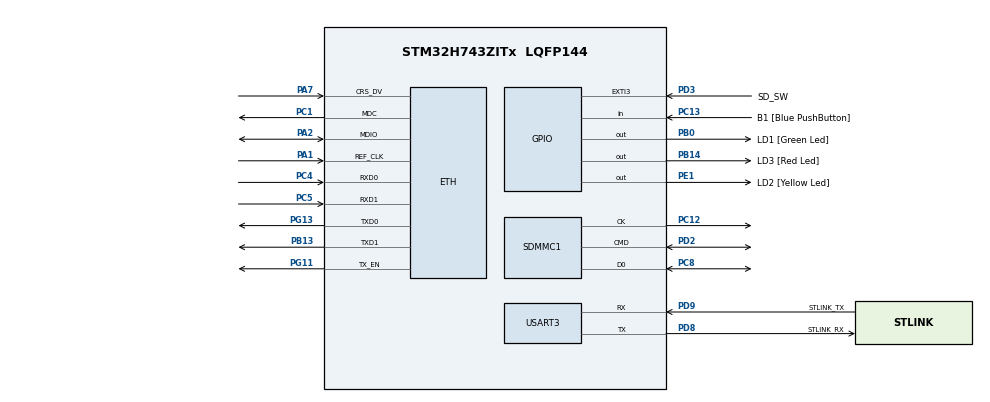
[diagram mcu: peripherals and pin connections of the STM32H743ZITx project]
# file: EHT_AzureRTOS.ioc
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CORTEX_M7.AccessPermission_S-Cortex_Memory_Protection_Unit_Region1_Settings_S=MPU_REGION_FULL_ACCESS
CORTEX_M7.AccessPermission_S-Cortex_Memory_Protection_Unit_Region2_Settings_S=MPU_REGION_FULL_ACCESS
CORTEX_M7.AccessPermission_Spec=MPU_REGION_NO_ACCESS
CORTEX_M7.BaseAddress_S-Cortex_Memory_Protection_Unit_Region1_Settings_S=0x24030000
CORTEX_M7.BaseAddress_S-Cortex_Memory_Protection_Unit_Region2_Settings_S=0x24030000
CORTEX_M7.CPU_DCache=Enabled
CORTEX_M7.CPU_ICache=Enabled
CORTEX_M7.Enable_S-Cortex_Memory_Protection_Unit_Region1_Settings_S=MPU_REGION_ENABLE
CORTEX_M7.Enable_S-Cortex_Memory_Protection_Unit_Region2_Settings_S=MPU_REGION_ENABLE
CORTEX_M7.IsBufferable_S-Cortex_Memory_Protection_Unit_Region2_Settings_S=MPU_ACCESS_BUFFERABLE
CORTEX_M7.Size_S-Cortex_Memory_Protection_Unit_Region1_Settings_S=MPU_REGION_SIZE_128KB
CORTEX_M7.Size_S-Cortex_Memory_Protection_Unit_Region2_Settings_S=MPU_REGION_SIZE_256B
CORTEX_M7.default_mode_Activation=1
ETH.MACAddr=00\:11\:83\:45\:26\:20
ETH.MediaInterface=HAL_ETH_RMII_MODE
ETH.RxDescAddress=0x24030000
ETH.TxDescAddress=0x24030060
Mcu.Family=STM32H7
Mcu.Name=STM32H743ZITx
Mcu.Package=LQFP144
NVIC.ETH_IRQn=true\:0\:0\:false\:false\:true\:false\:true\:true\:true
NVIC.EXTI3_IRQn=true\:0\:0\:false\:false\:true\:false\:true\:true\:true
NVIC.PriorityGroup=NVIC_PRIORITYGROUP_4
NVIC.SDMMC1_IRQn=true\:0\:0\:false\:false\:true\:false\:true\:true\:true
NVIC.TIM7_IRQn=true\:15\:0\:false\:false\:true\:false\:false\:true\:true
NVIC.TimeBase=TIM7_IRQn
NVIC.TimeBaseIP=TIM7
PA1.Mode=RMII
PA1.Signal=ETH_REF_CLK
PA11.Signal=USB_OTG_FS_DM
PA12.Signal=USB_OTG_FS_DP
PA13\ (JTMS/SWDIO).Mode=Trace_Asynchronous_SW
PA13\ (JTMS/SWDIO).Signal=DEBUG_JTMS-SWDIO
PA14\ (JTCK/SWCLK).Mode=Trace_Asynchronous_SW
PA14\ (JTCK/SWCLK).Signal=DEBUG_JTCK-SWCLK
PA2.Mode=RMII
PA2.Signal=ETH_MDIO
PA7.Mode=RMII
PA7.Signal=ETH_CRS_DV
PA8.Signal=USB_OTG_FS_SOF
PA9.Signal=USB_OTG_FS_VBUS
PB0.GPIO_Label=LD1 [Green Led]
PB0.Signal=GPIO_Output
PB13.Mode=RMII
PB13.Signal=ETH_TXD1
PB14.GPIO_Label=LD3 [Red Led]
PB14.Signal=GPIO_Output
PB3\ (JTDO/TRACESWO).Mode=Trace_Asynchronous_SW
PB3\ (JTDO/TRACESWO).Signal=DEBUG_JTDO-SWO
PC1.Mode=RMII
PC1.Signal=ETH_MDC
PC12.Mode=SD_1_bit
PC12.Signal=SDMMC1_CK
PC13.GPIO_Label=B1 [Blue PushButton]
PC13.Signal=GPIO_Input
PC14-OSC32_IN\ (OSC32_IN).Mode=LSE-External-Oscillator
PC14-OSC32_IN\ (OSC32_IN).Signal=RCC_OSC32_IN
PC15-OSC32_OUT\ (OSC32_OUT).Mode=LSE-External-Oscillator
PC15-OSC32_OUT\ (OSC32_OUT).Signal=RCC_OSC32_OUT
PC4.Mode=RMII
PC4.Signal=ETH_RXD0
PC5.Mode=RMII
PC5.Signal=ETH_RXD1
PC8.Mode=SD_1_bit
PC8.Signal=SDMMC1_D0
PD2.Mode=SD_1_bit
PD2.Signal=SDMMC1_CMD
PD3.GPIO_Label=SD_SW
PD3.Signal=GPXTI3
PD8.GPIO_Label=STLINK_RX
PD8.Mode=Asynchronous
PD8.Signal=USART3_TX
PD9.GPIO_Label=STLINK_TX
PD9.Mode=Asynchronous
PD9.Signal=USART3_RX
PE1.GPIO_Label=LD2 [Yellow Led]
PE1.Signal=GPIO_Output
PG11.Mode=RMII
PG11.Signal=ETH_TX_EN
PG13.Mode=RMII
PG13.Signal=ETH_TXD0
PH0-OSC_IN\ (PH0).Mode=HSE-External-Clock-Source
PH0-OSC_IN\ (PH0).Signal=RCC_OSC_IN
PH1-OSC_OUT\ (PH1).Signal=RCC_OSC_OUT
ProjectManager.HeapSize=0x200
ProjectManager.StackSize=0x400
ProjectManager.TargetToolchain=STM32CubeIDE
RCC.ADCFreq_Value=16125000
RCC.APB1Freq_Value=120000000
RCC.APB2Freq_Value=120000000
RCC.APB3Freq_Value=120000000
RCC.APB4Freq_Value=120000000
RCC.CortexFreq_Value=480000000
RCC.D1PPRE=RCC_APB3_DIV2
RCC.D2PPRE1=RCC_APB1_DIV2
RCC.D2PPRE2=RCC_APB2_DIV2
RCC.D3PPRE=RCC_APB4_DIV2
RCC.DIVM1=1
RCC.DIVN1=120
RCC.DIVQ1=10
RCC.HCLKFreq_Value=240000000
RCC.HPRE=RCC_HCLK_DIV2
RCC.HSE_VALUE=8000000
RCC.PLLFRACN=0
RCC.PLLSourceVirtual=RCC_PLLSOURCE_HSE
RCC.PWR_Regulator_Voltage_Scale=PWR_REGULATOR_VOLTAGE_SCALE2
RCC.SYSCLKFreq_VALUE=480000000
RCC.SYSCLKSource=RCC_SYSCLKSOURCE_PLLCLK
RCC.USBFreq_Value=96000000
STMicroelectronics.X-CUBE-AZRTOS-H7.3.1.0.FX_APP_MEM_POOL_SIZE=1024*4
STMicroelectronics.X-CUBE-AZRTOS-H7.3.1.0.FileXCcFileOoSystemJjFileXJjCore=true
STMicroelectronics.X-CUBE-AZRTOS-H7.3.1.0.Initialize_DHCP_protocol=true
STMicroelectronics.X-CUBE-AZRTOS-H7.3.1.0.Initialize_TCP_protocol=true
STMicroelectronics.X-CUBE-AZRTOS-H7.3.1.0.Initialize_UDP_protocol=true
STMicroelectronics.X-CUBE-AZRTOS-H7.3.1.0.InterfacesCcFileOoSystemJjFileXOoSDOointerface=true
STMicroelectronics.X-CUBE-AZRTOS-H7.3.1.0.InterfacesCcNetworkJjEthernetOoInterface=true
STMicroelectronics.X-CUBE-AZRTOS-H7.3.1.0.InterfacesCcNetworkJjEthernetOoPhyOoInterface=LAN8742IiPhyIiInterface
STMicroelectronics.X-CUBE-AZRTOS-H7.3.1.0.NX_APP_MEM_POOL_SIZE=45 * 1024
STMicroelectronics.X-CUBE-AZRTOS-H7.3.1.0.NX_ENABLE_INTERFACE_CAPABILITY=true
STMicroelectronics.X-CUBE-AZRTOS-H7.3.1.0.NetXDuoCcNetworkJjNetXDuoJjAddonsOoWebOoServer=true
STMicroelectronics.X-CUBE-AZRTOS-H7.3.1.0.NetXDuoCcNetworkJjNetXDuoJjNXOoCore=true
STMicroelectronics.X-CUBE-AZRTOS-H7.3.1.0.STM32CubeIiBSPIiComponentsCcBoardOoPartJjETHPhyJjLAN8742=true
STMicroelectronics.X-CUBE-AZRTOS-H7.3.1.0.TX_APP_MEM_POOL_SIZE=1024*2
STMicroelectronics.X-CUBE-AZRTOS-H7.3.1.0.ThreadXCcRTOSJjThreadXJjCore=true
STMicroelectronics.X-CUBE-AZRTOS-H7.3.1.0_IsAnAzureRtosMw=true
USART3.VirtualMode-Asynchronous=VM_ASYNC
VP_STMicroelectronics.X-CUBE-AZRTOS-H7_VS_BoardOoPartJjSTM32CubeIiBSPIiComponents_1.1.0_3.1.0.Mode=BoardOoPartJjSTM32CubeIiBSPIiComponents
VP_STMicroelectronics.X-CUBE-AZRTOS-H7_VS_FileOoSystemJjFileX_6.2.0_3.1.0.Mode=FileOoSystemJjFileX
VP_STMicroelectronics.X-CUBE-AZRTOS-H7_VS_FileOoSystemJjInterfaces_2.1.0_3.1.0.Mode=FileOoSystemJjInterfaces
VP_STMicroelectronics.X-CUBE-AZRTOS-H7_VS_NetworkJjInterfaces_2.1.0_3.1.0.Mode=NetworkJjInterfaces
VP_STMicroelectronics.X-CUBE-AZRTOS-H7_VS_NetworkJjNetXDuo_6.2.0_3.1.0.Mode=NetworkJjNetXDuo
VP_STMicroelectronics.X-CUBE-AZRTOS-H7_VS_RTOSJjThreadX_6.2.0_3.1.0.Mode=RTOSJjThreadX
VP_SYS_VS_tim7.Mode=TIM7
board=NUCLEO-H743ZI2

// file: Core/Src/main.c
/* USER CODE BEGIN Header */
/**
  ******************************************************************************
  * @file           : main.c
  * @brief          : Main program body
  ******************************************************************************
  * @attention
  *
  * Copyright (c) 2023 STMicroelectronics.
  * All rights reserved.
  *
  * This software is licensed under terms that can be found in the LICENSE file
  * in the root directory of this software component.
  * If no LICENSE file comes with this software, it is provided AS-IS.
  *
  ******************************************************************************
  */
/* USER CODE END Header */
#include "app_threadx.h"
#include "main.h"
#include "eth.h"
#include "sdmmc.h"
#include "usart.h"
#include "gpio.h"

void SystemClock_Config(void);
static void MPU_Initialize(void);
static void MPU_Config(void);

/* USER CODE BEGIN 0 */
int __io_putchar(int ch){
	ITM_SendChar(ch);
	HAL_UART_Transmit(&huart3, (uint8_t *)&ch, 1, 0xFFFF);
	return ch;
}
/* USER CODE END 0 */

int main(void)
{

  /* Enable I-Cache---------------------------------------------------------*/
  SCB_EnableICache();

  /* Enable D-Cache---------------------------------------------------------*/
  SCB_EnableDCache();

  /* MCU Configuration--------------------------------------------------------*/

  /* Reset of all peripherals, Initializes the Flash interface and the Systick. */
  HAL_Init();

  /* MPU Configuration--------------------------------------------------------*/
  MPU_Config();

  /* Configure the system clock */
  SystemClock_Config();

  /* Initialize all configured peripherals */
  MX_GPIO_Init();
  MX_ETH_Init();
  MX_USART3_UART_Init();
  MX_SDMMC1_SD_Init();

  MX_ThreadX_Init();

  /* We should never get here as control is now taken by the scheduler */
  /* Infinite loop */
  while (1)
  {

  }
}

void SystemClock_Config(void)
{
  RCC_OscInitTypeDef RCC_OscInitStruct = {0};
  RCC_ClkInitTypeDef RCC_ClkInitStruct = {0};

  /** Supply configuration update enable
  */
  HAL_PWREx_ConfigSupply(PWR_LDO_SUPPLY);

  /** Configure the main internal regulator output voltage
  */
  __HAL_PWR_VOLTAGESCALING_CONFIG(PWR_REGULATOR_VOLTAGE_SCALE1);
  while(!__HAL_PWR_GET_FLAG(PWR_FLAG_VOSRDY)) {}

  /** Initializes the RCC Oscillators according to the specified parameters
  * in the RCC_OscInitTypeDef structure.
  */
  RCC_OscInitStruct.OscillatorType = RCC_OSCILLATORTYPE_HSE;
  RCC_OscInitStruct.HSEState = RCC_HSE_BYPASS;
  RCC_OscInitStruct.PLL.PLLState = RCC_PLL_ON;
  RCC_OscInitStruct.PLL.PLLSource = RCC_PLLSOURCE_HSE;
  RCC_OscInitStruct.PLL.PLLM = 1;
  RCC_OscInitStruct.PLL.PLLN = 120;
  RCC_OscInitStruct.PLL.PLLP = 2;
  RCC_OscInitStruct.PLL.PLLQ = 10;
  RCC_OscInitStruct.PLL.PLLR = 2;
  RCC_OscInitStruct.PLL.PLLRGE = RCC_PLL1VCIRANGE_3;
  RCC_OscInitStruct.PLL.PLLVCOSEL = RCC_PLL1VCOWIDE;
  RCC_OscInitStruct.PLL.PLLFRACN = 0;
  if (HAL_RCC_OscConfig(&RCC_OscInitStruct) != HAL_OK)
  {
    Error_Handler();
  }

  /** Initializes the CPU, AHB and APB buses clocks
  */
  RCC_ClkInitStruct.ClockType = RCC_CLOCKTYPE_HCLK|RCC_CLOCKTYPE_SYSCLK
                              |RCC_CLOCKTYPE_PCLK1|RCC_CLOCKTYPE_PCLK2
                              |RCC_CLOCKTYPE_D3PCLK1|RCC_CLOCKTYPE_D1PCLK1;
  RCC_ClkInitStruct.SYSCLKSource = RCC_SYSCLKSOURCE_PLLCLK;
  RCC_ClkInitStruct.SYSCLKDivider = RCC_SYSCLK_DIV1;
  RCC_ClkInitStruct.AHBCLKDivider = RCC_HCLK_DIV2;
  RCC_ClkInitStruct.APB3CLKDivider = RCC_APB3_DIV2;
  RCC_ClkInitStruct.APB1CLKDivider = RCC_APB1_DIV2;
  RCC_ClkInitStruct.APB2CLKDivider = RCC_APB2_DIV2;
  RCC_ClkInitStruct.APB4CLKDivider = RCC_APB4_DIV2;

  if (HAL_RCC_ClockConfig(&RCC_ClkInitStruct, FLASH_LATENCY_4) != HAL_OK)
  {
    Error_Handler();
  }
}

/* MPU Configuration */

void MPU_Config(void)
{
  MPU_Region_InitTypeDef MPU_InitStruct = {0};

  /* Disables the MPU */
  HAL_MPU_Disable();

  /** Initializes and configures the Region and the memory to be protected
  */
  MPU_InitStruct.Enable = MPU_REGION_ENABLE;
  MPU_InitStruct.Number = MPU_REGION_NUMBER0;
  MPU_InitStruct.BaseAddress = 0x0;
  MPU_InitStruct.Size = MPU_REGION_SIZE_4GB;
  MPU_InitStruct.SubRegionDisable = 0x87;
  MPU_InitStruct.TypeExtField = MPU_TEX_LEVEL0;
  MPU_InitStruct.AccessPermission = MPU_REGION_NO_ACCESS;
  MPU_InitStruct.DisableExec = MPU_INSTRUCTION_ACCESS_DISABLE;
  MPU_InitStruct.IsShareable = MPU_ACCESS_SHAREABLE;
  MPU_InitStruct.IsCacheable = MPU_ACCESS_NOT_CACHEABLE;
  MPU_InitStruct.IsBufferable = MPU_ACCESS_NOT_BUFFERABLE;

  HAL_MPU_ConfigRegion(&MPU_InitStruct);

  /** Initializes and configures the Region and the memory to be protected
  */
  MPU_InitStruct.Number = MPU_REGION_NUMBER1;
  MPU_InitStruct.BaseAddress = 0x24030000;
  MPU_InitStruct.Size = MPU_REGION_SIZE_128KB;
  MPU_InitStruct.SubRegionDisable = 0x0;
  MPU_InitStruct.AccessPermission = MPU_REGION_FULL_ACCESS;
  MPU_InitStruct.DisableExec = MPU_INSTRUCTION_ACCESS_ENABLE;
  MPU_InitStruct.IsShareable = MPU_ACCESS_NOT_SHAREABLE;

  HAL_MPU_ConfigRegion(&MPU_InitStruct);

  /** Initializes and configures the Region and the memory to be protected
  */
  MPU_InitStruct.Number = MPU_REGION_NUMBER2;
  MPU_InitStruct.Size = MPU_REGION_SIZE_256B;
  MPU_InitStruct.IsBufferable = MPU_ACCESS_BUFFERABLE;

  HAL_MPU_ConfigRegion(&MPU_InitStruct);
  /* Enables the MPU */
  HAL_MPU_Enable(MPU_PRIVILEGED_DEFAULT);

}

void HAL_TIM_PeriodElapsedCallback(TIM_HandleTypeDef *htim)
{
  if (htim->Instance == TIM7) {
    HAL_IncTick();
  }
}

void Error_Handler(void)
{
  __disable_irq();
  while (1)
  {
  }
}
